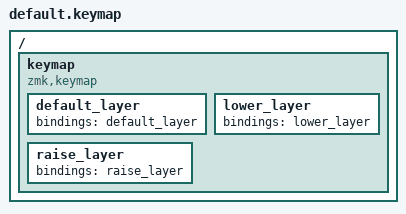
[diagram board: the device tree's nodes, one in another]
/ {
    keymap {
        compatible = "zmk,keymap";

        default_layer {
            bindings = <&default_layer>;
        };

        lower_layer {
            bindings = <&lower_layer>;
        };

        raise_layer {
            bindings = <&raise_layer>;
        };
    };
};
